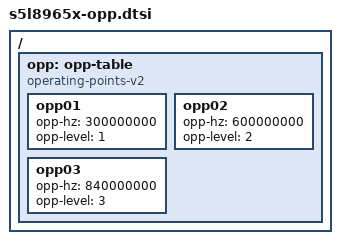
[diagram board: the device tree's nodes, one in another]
// SPDX-License-Identifier: GPL-2.0+ OR MIT
/*
 * Operating points for Apple S5L8965X "A7" Rev A SoC, Up to 1392 MHz
 *
 * target-type: J71, J72, J73
 *
 * Copyright (c) 2024, Nick Chan <towinchenmi@gmail.com>
 */

/ {
	opp: opp-table {
		compatible = "operating-points-v2";

		opp01 {
			opp-hz = /bits/ 64 <300000000>;
			opp-level = <1>;
		};

		opp02 {
			opp-hz = /bits/ 64 <600000000>;
			opp-level = <2>;
		};

		opp03 {
			opp-hz = /bits/ 64 <840000000>;
			opp-level = <3>;
		};

#if 0
		/* !! FIXME !! SoC Wedges */
		opp04 {
			opp-hz = /bits/ 64 <1128000000>;
			opp-level = <4>;
		};

		opp05 {
			opp-hz = /bits/ 64 <1296000000>;
			opp-level = <5>;
		};

		opp06 {
			opp-hz = /bits/ 64 <1392000000>;
			opp-level = <6>;
		};
#endif
	};
};
